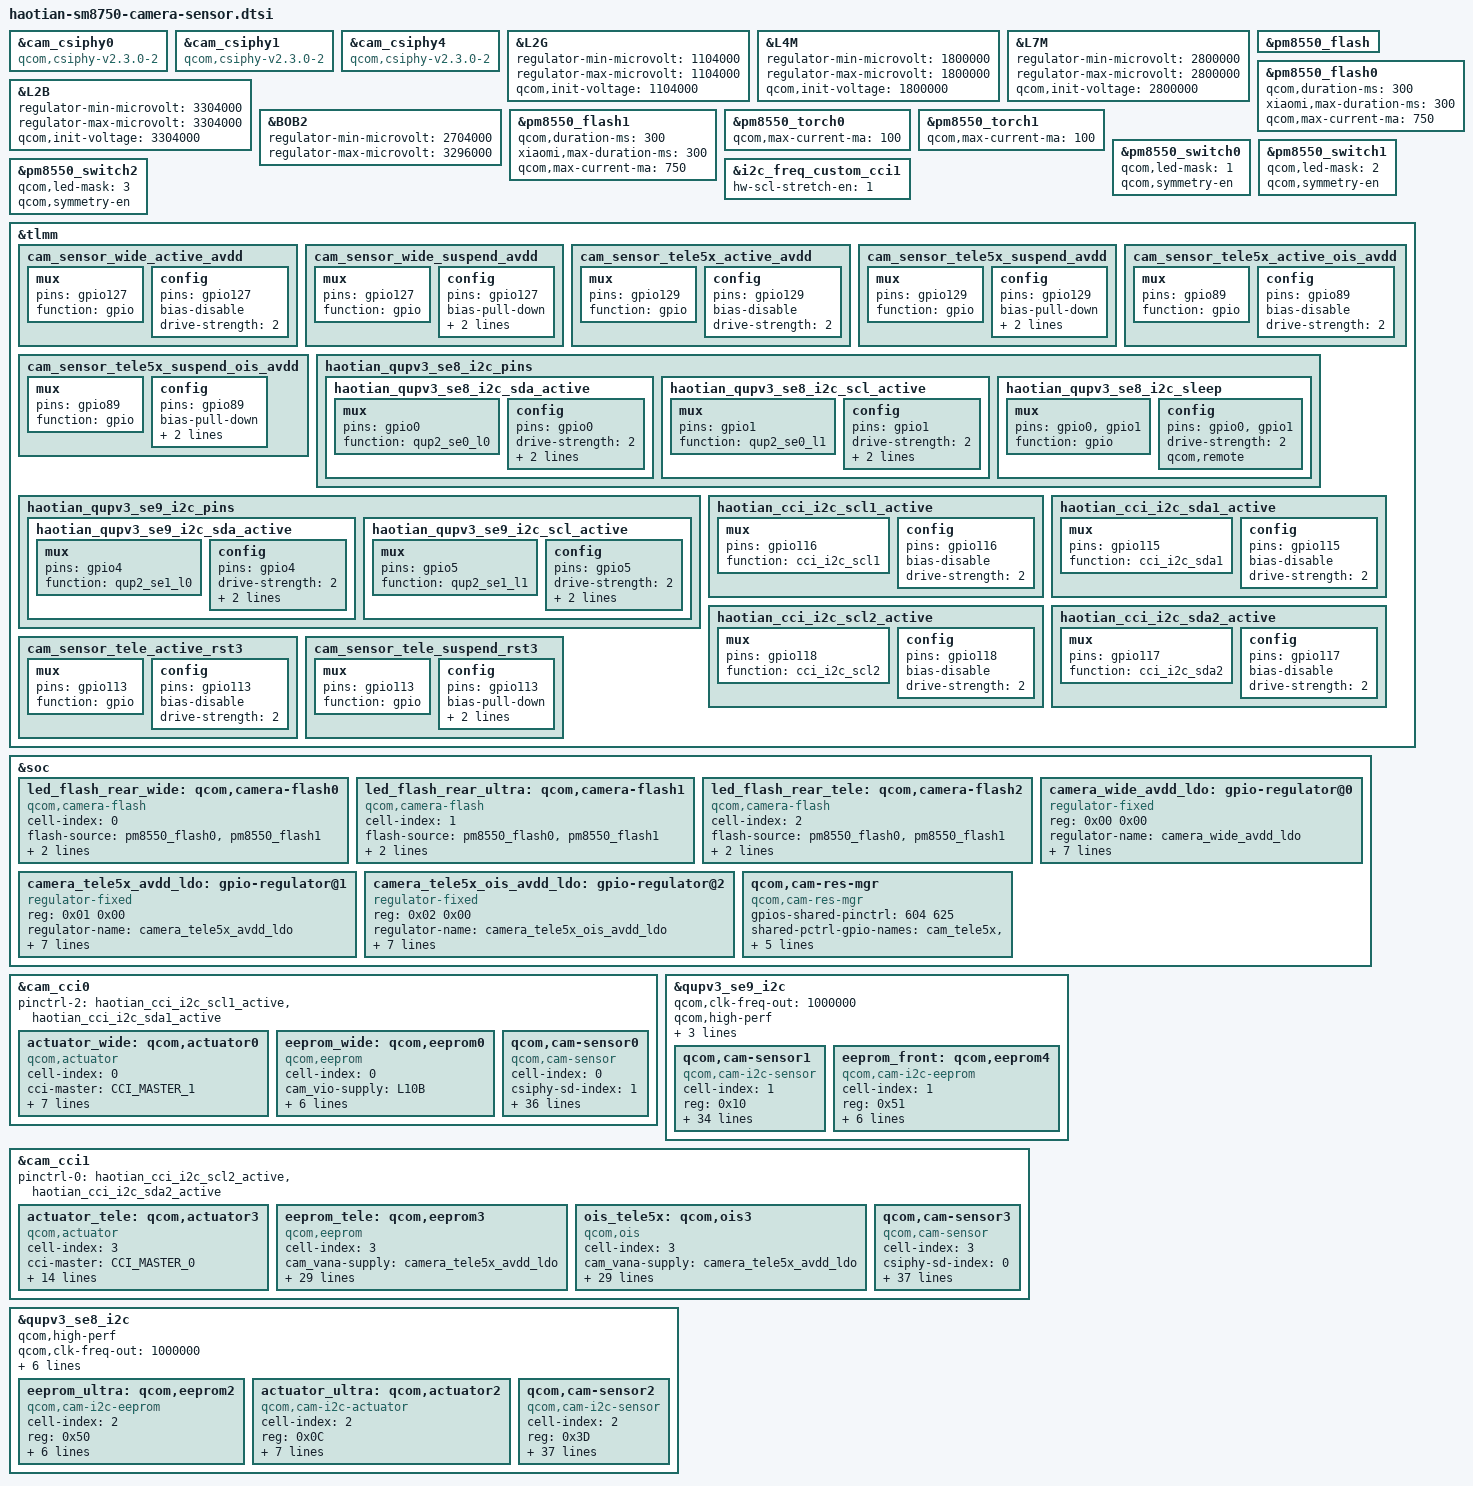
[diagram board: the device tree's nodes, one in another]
#include <dt-bindings/msm-camera.h>

// tele5x
&cam_csiphy0 {
	compatible = "qcom,csiphy-v2.3.0-2", "qcom,csiphy";
};

// Wide
&cam_csiphy1 {
	compatible = "qcom,csiphy-v2.3.0-2", "qcom,csiphy";
};

// Front
&cam_csiphy4 {
	compatible = "qcom,csiphy-v2.3.0-2", "qcom,csiphy";
};

&L2G {
	regulator-min-microvolt = <1104000>;
	regulator-max-microvolt = <1104000>;
	qcom,init-voltage = <1104000>;
};

&L4M {
	regulator-min-microvolt = <1800000>;
	regulator-max-microvolt = <1800000>;
	qcom,init-voltage = <1800000>;
};

&L7M {
	regulator-min-microvolt = <2800000>;
	regulator-max-microvolt = <2800000>;
	qcom,init-voltage = <2800000>;
};

&L2B {
	regulator-min-microvolt = <3304000>;
	regulator-max-microvolt = <3304000>;
	qcom,init-voltage = <3304000>;
};

&BOB2 {
	regulator-min-microvolt = <2704000>;
	regulator-max-microvolt = <3296000>;
};

&pm8550_flash {
	status = "ok";
};

&pm8550_flash0 {
	qcom,duration-ms = <300>;
	xiaomi,max-duration-ms = <300>;
	qcom,max-current-ma = <750>;
};

&pm8550_flash1 {
	qcom,duration-ms = <300>;
	xiaomi,max-duration-ms = <300>;
	qcom,max-current-ma = <750>;
};

&pm8550_torch0{
	qcom,max-current-ma = <100>;
};

&pm8550_torch1{
	qcom,max-current-ma = <100>;
};

&pm8550_switch0 {
	qcom,led-mask = <1>;
	qcom,symmetry-en;
};

&pm8550_switch1 {
	qcom,led-mask = <2>;
	qcom,symmetry-en;
};

&pm8550_switch2 {
	qcom,led-mask = <3>;
	qcom,symmetry-en;
};

&i2c_freq_custom_cci1{
	hw-scl-stretch-en = <1>;
};

&tlmm {
	cam_sensor_wide_active_avdd: cam_sensor_wide_active_avdd {
		mux {
			pins = "gpio127";
			function = "gpio";
		};

		config {
			pins = "gpio127";
			bias-disable; /* No PULL */
			drive-strength = <2>; /* 2 MA */
		};
	};

	cam_sensor_wide_suspend_avdd: cam_sensor_wide_suspend_avdd {
		mux {
			pins = "gpio127";
			function = "gpio";
		};

		config {
			pins = "gpio127";
			bias-pull-down; /* PULL DOWN */
			drive-strength = <2>; /* 2 MA */
			output-low;
		};
	};

	cam_sensor_tele5x_active_avdd: cam_sensor_tele5x_active_avdd {
		mux {
			pins = "gpio129";
			function = "gpio";
		};

		config {
			pins = "gpio129";
			bias-disable; /* No PULL */
			drive-strength = <2>; /* 2 MA */
		};
	};

	cam_sensor_tele5x_suspend_avdd: cam_sensor_tele5x_suspend_avdd {
		mux {
			pins = "gpio129";
			function = "gpio";
		};

		config {
			pins = "gpio129";
			bias-pull-down; /* PULL DOWN */
			drive-strength = <2>; /* 2 MA */
			output-low;
		};
	};

	cam_sensor_tele5x_active_ois_avdd: cam_sensor_tele5x_active_ois_avdd {
		mux {
			pins = "gpio89";
			function = "gpio";
		};

		config {
			pins = "gpio89";
			bias-disable; /* No PULL */
			drive-strength = <2>; /* 2 MA */
		};
	};

	cam_sensor_tele5x_suspend_ois_avdd: cam_sensor_tele5x_suspend_ois_avdd {
		mux {
			pins = "gpio89";
			function = "gpio";
		};

		config {
			pins = "gpio89";
			bias-pull-down; /* PULL DOWN */
			drive-strength = <2>; /* 2 MA */
			output-low;
		};
	};

	haotian_qupv3_se8_i2c_pins: haotian_qupv3_se8_i2c_pins {
		haotian_qupv3_se8_i2c_sda_active: haotian_qupv3_se8_i2c_sda_active {
			mux {
				pins = "gpio0";
				function = "qup2_se0_l0";
			};

			config {
				pins = "gpio0";
				drive-strength = <2>;
				bias-disable;
				qcom,apps;
			};
		};

		haotian_qupv3_se8_i2c_scl_active: haotian_qupv3_se8_i2c_scl_active {
			mux {
				pins = "gpio1";
				function = "qup2_se0_l1";
			};

			config {
				pins = "gpio1";
				drive-strength = <2>;
				bias-disable;
				qcom,apps;
			};
		};

		haotian_qupv3_se8_i2c_sleep: haotian_qupv3_se8_i2c_sleep {
			mux {
				pins = "gpio0", "gpio1";
				function = "gpio";
			};

			config {
				pins = "gpio0", "gpio1";
				drive-strength = <2>;
				qcom,remote;
			};
		};
	};


	haotian_qupv3_se9_i2c_pins: haotian_qupv3_se9_i2c_pins {
		haotian_qupv3_se9_i2c_sda_active: haotian_qupv3_se9_i2c_sda_active {
			mux {
				pins = "gpio4";
				function = "qup2_se1_l0";
			};

			config {
				pins = "gpio4";
				drive-strength = <2>;
				bias-disable;
				qcom,apps;
			};
		};

		haotian_qupv3_se9_i2c_scl_active: haotian_qupv3_se9_i2c_scl_active {
			mux {
				pins = "gpio5";
				function = "qup2_se1_l1";
			};

			config {
				pins = "gpio5";
				drive-strength = <2>;
				bias-disable;
				qcom,apps;
			};
		};
	};

	haotian_cci_i2c_scl1_active: haotian_cci_i2c_scl1_active {
		mux {
			/* CLK, DATA */
			pins = "gpio116";
			function = "cci_i2c_scl1";
		};

		config {
			pins = "gpio116";
			bias-disable; /* NO PULL */
			drive-strength = <2>; /* 2 MA */
		};
	};

	haotian_cci_i2c_sda1_active: haotian_cci_i2c_sda1_active {
		mux {
			/* CLK, DATA */
			pins = "gpio115";
			function = "cci_i2c_sda1";
		};

		config {
			pins = "gpio115";
			bias-disable; /* NO PULL */
			drive-strength = <2>; /* 2 MA */
		};
	};

	haotian_cci_i2c_scl2_active: haotian_cci_i2c_scl2_active {
		mux {
			/* CLK, DATA */
			pins = "gpio118";
			function = "cci_i2c_scl2";
		};

		config {
			pins = "gpio118";
			bias-disable; /* NO PULL */
			drive-strength = <2>; /* 2 MA */
		};
	};

	haotian_cci_i2c_sda2_active: haotian_cci_i2c_sda2_active {
		mux {
			/* CLK, DATA */
			pins = "gpio117";
			function = "cci_i2c_sda2";
		};

		config {
			pins = "gpio117";
			bias-disable; /* NO PULL */
			drive-strength = <2>; /* 2 MA */
		};
	};

	cam_sensor_tele_active_rst3: cam_sensor_tele_active_rst3 {
		mux {
			pins = "gpio113";
			function = "gpio";
		};

		config {
			pins = "gpio113";
			bias-disable; /* No PULL */
			drive-strength = <2>; /* 2 MA */
		};
	};

	cam_sensor_tele_suspend_rst3: cam_sensor_tele_suspend_rst3 {
		mux {
			pins = "gpio113";
			function = "gpio";
		};

		config {
			pins = "gpio113";
			bias-pull-down; /* PULL DOWN */
			drive-strength = <2>; /* 2 MA */
			output-low;
		};
	};
};

&soc {
	led_flash_rear_wide: qcom,camera-flash0 {
		cell-index = <0>;
		compatible = "qcom,camera-flash";
		flash-source = <&pm8550_flash0 &pm8550_flash1>;
		torch-source = <&pm8550_torch0 &pm8550_torch1>;
		switch-source = <&pm8550_switch2>;
		status = "ok";
	};

	led_flash_rear_ultra: qcom,camera-flash1 {
		cell-index = <1>;
		compatible = "qcom,camera-flash";
		flash-source = <&pm8550_flash0 &pm8550_flash1>;
		torch-source = <&pm8550_torch0 &pm8550_torch1>;
		switch-source = <&pm8550_switch2>;
		status = "ok";
	};

	led_flash_rear_tele: qcom,camera-flash2 {
		cell-index = <2>;
		compatible = "qcom,camera-flash";
		flash-source = <&pm8550_flash0 &pm8550_flash1>;
		torch-source = <&pm8550_torch0 &pm8550_torch1>;
		switch-source = <&pm8550_switch2>;
		status = "ok";
	};

	camera_wide_avdd_ldo: gpio-regulator@0 {
		compatible = "regulator-fixed";
		reg = <0x00 0x00>;
		regulator-name = "camera_wide_avdd_ldo";
		regulator-min-microvolt = <2800000>;
		regulator-max-microvolt = <2800000>;
		regulator-enable-ramp-delay = <100>;
		enable-active-high;
		gpio = <&tlmm 127 0>;
		pinctrl-names = "wide_avdd_active", "wide_avdd_suspend";
		pinctrl-0 = <&cam_sensor_wide_active_avdd
					 &cam_sensor_wide_suspend_avdd>;
	};

	camera_tele5x_avdd_ldo: gpio-regulator@1 {
		compatible = "regulator-fixed";
		reg = <0x01 0x00>;
		regulator-name = "camera_tele5x_avdd_ldo";
		regulator-min-microvolt = <2800000>;
		regulator-max-microvolt = <2800000>;
		regulator-enable-ramp-delay = <100>;
		enable-active-high;
		gpio = <&tlmm 129 0>;
		pinctrl-names = "tele5x_avdd_active", "tele5x_avdd_suspend";
		pinctrl-0 = <&cam_sensor_tele5x_active_avdd
					 &cam_sensor_tele5x_suspend_avdd>;
	};

	camera_tele5x_ois_avdd_ldo: gpio-regulator@2 {
		compatible = "regulator-fixed";
		reg = <0x02 0x00>;
		regulator-name = "camera_tele5x_ois_avdd_ldo";
		regulator-min-microvolt = <2800000>;
		regulator-max-microvolt = <2800000>;
		regulator-enable-ramp-delay = <100>;
		enable-active-high;
		gpio = <&tlmm 89 0>;
		pinctrl-names = "tele5x_ois_avdd_active", "tele5x_ois_avdd_suspend";
		pinctrl-0 = <&cam_sensor_tele5x_active_ois_avdd
					 &cam_sensor_tele5x_suspend_ois_avdd>;
	};

	qcom,cam-res-mgr {
		compatible = "qcom,cam-res-mgr";
		gpios-shared-pinctrl = <604 625>;
		shared-pctrl-gpio-names = "cam_tele5x", "cam_tele5x";
		pinctrl-names = "cam_tele5x_active", "cam_tele5x_suspend";
		pinctrl-0 = <&cam_sensor_mclk3_active
					&cam_sensor_tele_active_rst3>;
		pinctrl-1 = <&cam_sensor_mclk3_suspend
					&cam_sensor_tele_suspend_rst3>;
		status = "ok";
	};
};

&cam_cci0 {
	pinctrl-2 = <&haotian_cci_i2c_scl1_active &haotian_cci_i2c_sda1_active>;

	// wide actuator
	actuator_wide: qcom,actuator0 {
		cell-index = <0>;
		compatible = "qcom,actuator";
		cci-master = <CCI_MASTER_1>;
		cam_vaf-supply = <&L2B>;
		cam_vio-supply = <&L10B>;
		regulator-names = "cam_vaf", "cam_vio";
		rgltr-cntrl-support;
		rgltr-min-voltage = <3304000 1800000>;
		rgltr-max-voltage = <3304000 1800000>;
		rgltr-load-current = <150000 150000>;
	};

	eeprom_wide: qcom,eeprom0 {
		cell-index = <0>;
		compatible = "qcom,eeprom";
		cam_vio-supply = <&L10B>;
		regulator-names = "cam_vio";
		rgltr-cntrl-support;
		rgltr-min-voltage = <1800000>;
		rgltr-max-voltage = <1800000>;
		rgltr-load-current = <50000>;
		cci-master = <CCI_MASTER_1>;
		status = "ok";
	};

	// wide sensor
	qcom,cam-sensor0 {
		cell-index = <0>;
		compatible = "qcom,cam-sensor";
		csiphy-sd-index = <1>;
		eeprom-src = <&eeprom_wide>;
		actuator-src = <&actuator_wide>;
		led-flash-src = <&led_flash_rear_wide>;
		sensor-position-roll = <90>;
		sensor-position-pitch = <0>;
		sensor-position-yaw = <180>;
		cam_vana-supply = <&camera_wide_avdd_ldo>;
		cam_vio-supply = <&L10B>;
		cam_vdig-supply = <&L1I>;
		cam_clk-supply = <&cam_cc_titan_top_gdsc>;
		cam_vaf-supply = <&L2B>;
		cam_bob2-supply = <&BOB2>;
		regulator-names = "cam_vana", "cam_vio", "cam_vdig",
			"cam_clk","cam_vaf", "cam_bob2";
		rgltr-cntrl-support;
		rgltr-min-voltage = <2800000 1800000 1200000 0 3304000 2704000>;
		rgltr-max-voltage = <2800000 1800000 1200000 0 3304000 3296000>;
		rgltr-load-current = <150000 150000 150000 0 150000 2000000>;
		gpio-no-mux = <0>;
		pinctrl-names = "cam_default", "cam_suspend";
		pinctrl-0 = <&cam_sensor_mclk1_active &cam_sensor_i3cSelect_active>;
		pinctrl-1 = <&cam_sensor_mclk1_suspend &cam_sensor_i3cSelect_suspend>;
		gpios = <&tlmm 90 0>, <&tlmm 6 0>;
		gpio-reset = <1>;
		gpio-req-tbl-num = <0 1>;
		gpio-req-tbl-flags = <1 0>;
		gpio-req-tbl-label = "CAMIF_MCLK1", "CAM_I3CSELECT";
		cci-master = <CCI_MASTER_1>;
		clocks = <&cambistmclkcc CAM_BIST_MCLK_CC_MCLK1_CLK>;
		clock-names = "cam_clk";
		clock-cntl-level = "nominal";
		clock-rates = <19200000>;
		status = "ok";
	};
};

&qupv3_se9_i2c {
	status = "ok";
	qcom,clk-freq-out = <1000000>;
	qcom,high-perf;
	qcom,pm-ctrl-client;
	pinctrl-0 = <&haotian_qupv3_se9_i2c_scl_active>, <&haotian_qupv3_se9_i2c_sda_active>;

	// Front Sensor
	qcom,cam-sensor1 {
		cell-index = <1>;
		reg = <0x10>;
		compatible = "qcom,cam-i2c-sensor";
		csiphy-sd-index = <4>;
		eeprom-src = <&eeprom_front>;
		sensor-position-roll = <270>;
		sensor-position-pitch = <0>;
		sensor-position-yaw = <0>;
		cam_vana-supply = <&L3M>;
		cam_vio-supply = <&L5M>;
		cam_vdig-supply = <&L1M>;
		cam_clk-supply = <&cam_cc_titan_top_gdsc>;
		cam_bob2-supply = <&BOB2>;
		regulator-names = "cam_vana", "cam_vio",
			"cam_vdig", "cam_clk", "cam_bob2";
		rgltr-cntrl-support;
		aon-camera-id = <AON_CAM1>;
		rgltr-min-voltage = <2800000 1800000 1104000 0 2704000>;
		rgltr-max-voltage = <2800000 1800000 1104000 0 3296000>;
		rgltr-load-current = <150000 150000 150000 0 2000000>;
		gpio-no-mux = <0>;
		pinctrl-names = "cam_default", "cam_suspend";
		pinctrl-0 = <&cam_sensor_mclk4_active
			&cam_sensor_active_rst4>;
		pinctrl-1 = <&cam_sensor_mclk4_suspend
			&cam_sensor_suspend_rst4>;
		gpios = <&tlmm 93 0>, <&tlmm 7 0>;
		gpio-reset = <1>;
		gpio-req-tbl-num = <0 1>;
		gpio-req-tbl-flags = <1 0>;
		gpio-req-tbl-label = "CAMIF_MCLK4", "CAM_RESET4";
		clocks = <&cambistmclkcc CAM_BIST_MCLK_CC_MCLK4_CLK>;
		clock-names = "cam_clk";
		clock-cntl-level = "nominal";
		clock-rates = <19200000>;
		status = "ok";
	};

	//front
	eeprom_front: qcom,eeprom4 {
		cell-index = <1>;
		reg = <0x51>;
		compatible = "qcom,cam-i2c-eeprom";
		cam_vio-supply = <&L5M>;
		regulator-names = "cam_vio";
		rgltr-cntrl-support;
		rgltr-min-voltage = <1800000>;
		rgltr-max-voltage = <1800000>;
		rgltr-load-current = <150000>;
		status = "ok";
	};

};

&cam_cci1 {
	pinctrl-0 = <&haotian_cci_i2c_scl2_active &haotian_cci_i2c_sda2_active>;

	actuator_tele: qcom,actuator3 {
		cell-index = <3>;
		compatible = "qcom,actuator";
		cci-master = <CCI_MASTER_0>;
		cam_vaf-supply = <&L16B>;
		cam_vio-supply = <&L10B>;
		cam_v_custom1-supply = <&camera_tele5x_ois_avdd_ldo>;/*OIS AVDD*/
		cam_bob2-supply = <&BOB2>;
		regulator-names = "cam_vaf", "cam_vio", "cam_v_custom1", "cam_bob2";
		rgltr-cntrl-support;
		rgltr-min-voltage = <2800000 1800000 2800000 2704000>;
		rgltr-max-voltage = <2800000 1800000 2800000 3296000>;
		rgltr-load-current = <150000 20000 150000 2000000>;
		status = "ok";
	};

	eeprom_tele: qcom,eeprom3 {
		cell-index = <3>;
		compatible = "qcom,eeprom";
		cam_vana-supply = <&camera_tele5x_avdd_ldo>;
		cam_vio-supply = <&L10B>;
		cam_vdig-supply = <&L2G>;
		cam_vaf-supply = <&L16B>;
		cam_v_custom1-supply = <&camera_tele5x_ois_avdd_ldo>;/*OIS AVDD*/
		cam_bob2-supply = <&BOB2>;
		cam_clk-supply = <&cam_cc_titan_top_gdsc>;
		regulator-names = "cam_vana", "cam_vio", "cam_vdig",
			"cam_vaf", "cam_v_custom1", "cam_clk", "cam_bob2";
		rgltr-cntrl-support;
		rgltr-min-voltage = <2800000 1800000 1104000 2800000 2800000 0 2704000>;
		rgltr-max-voltage = <2800000 1800000 1104000 2800000 2800000 0 3296000>;
		rgltr-load-current = <150000 150000 150000 150000 150000 0 2000000>;
		gpio-no-mux = <0>;
		use-shared-clk;
		gpios = <&tlmm 92 0>, <&tlmm 113 0>;
		gpio-reset = <1>;
		gpio-req-tbl-num = <0 1>;
		gpio-req-tbl-flags = <1 0>;
		gpio-req-tbl-label = "CAMIF_MCLK3", "CAM_RESET_TELE5X";
		cci-master = <CCI_MASTER_0>;
		clocks = <&cambistmclkcc CAM_BIST_MCLK_CC_MCLK3_CLK>;
		clock-names = "cam_clk";
		clock-cntl-level = "nominal";
		clock-rates = <19200000>;
		status = "ok";
	};

	ois_tele5x: qcom,ois3 {
		cell-index = <3>;
		compatible = "qcom,ois";
		cam_vana-supply = <&camera_tele5x_avdd_ldo>;
		cam_vio-supply = <&L10B>;
		cam_vdig-supply = <&L2G>;
		cam_vaf-supply = <&L16B>;
		cam_v_custom1-supply = <&camera_tele5x_ois_avdd_ldo>;/*OIS AVDD*/
		cam_bob2-supply = <&BOB2>;
		cam_clk-supply = <&cam_cc_titan_top_gdsc>;
		regulator-names = "cam_vana", "cam_vio", "cam_vdig",
			"cam_vaf", "cam_v_custom1", "cam_clk", "cam_bob2";
		rgltr-cntrl-support;
		rgltr-min-voltage = <2800000 1800000 1104000 2800000 2800000 0 2704000>;
		rgltr-max-voltage = <2800000 1800000 1104000 2800000 2800000 0 3296000>;
		rgltr-load-current = <150000 150000 150000 150000 150000 0 2000000>;
		gpio-no-mux = <0>;
		use-shared-clk;
		gpios = <&tlmm 92 0>, <&tlmm 113 0>;
		gpio-reset = <1>;
		gpio-req-tbl-num = <0 1>;
		gpio-req-tbl-flags = <1 0>;
		gpio-req-tbl-label = "CAMIF_MCLK3", "CAM_RESET_TELE5X";
		cci-master = <CCI_MASTER_0>;
		clocks = <&cambistmclkcc CAM_BIST_MCLK_CC_MCLK3_CLK>;
		clock-names = "cam_clk";
		clock-cntl-level = "nominal";
		clock-rates = <19200000>;
		status = "ok";
	};

	// Tele5x sensor
	qcom,cam-sensor3 {
		cell-index = <3>;
		compatible = "qcom,cam-sensor";
		csiphy-sd-index = <0>;
		eeprom-src = <&eeprom_tele>;
		actuator-src = <&actuator_tele>;
		ois-src = <&ois_tele5x>;
		led-flash-src = <&led_flash_rear_tele>;
		sensor-position-roll = <90>;
		sensor-position-pitch = <0>;
		sensor-position-yaw = <180>;
		cam_vana-supply = <&camera_tele5x_avdd_ldo>;
		cam_vio-supply = <&L10B>;
		cam_vdig-supply = <&L2G>;
		cam_vaf-supply = <&L16B>;
		cam_v_custom1-supply = <&camera_tele5x_ois_avdd_ldo>;/*OIS AVDD*/
		cam_bob2-supply = <&BOB2>;
		cam_clk-supply = <&cam_cc_titan_top_gdsc>;
		regulator-names = "cam_vana", "cam_vio", "cam_vdig",
			"cam_vaf", "cam_v_custom1", "cam_clk", "cam_bob2";
		rgltr-cntrl-support;
		rgltr-min-voltage = <2800000 1800000 1104000 2800000 2800000 0 2704000>;
		rgltr-max-voltage = <2800000 1800000 1104000 2800000 2800000 0 3296000>;
		rgltr-load-current = <150000 150000 150000 150000 150000 0 2000000>;
		gpio-no-mux = <0>;
		use-shared-clk;
		gpios = <&tlmm 92 0>, <&tlmm 113 0>;
		gpio-reset = <1>;
		gpio-req-tbl-num = <0 1>;
		gpio-req-tbl-flags = <1 0>;
		gpio-req-tbl-label = "CAMIF_MCLK3", "CAM_RESET_TELE5X";
		cci-master = <CCI_MASTER_0>;
		clocks = <&cambistmclkcc CAM_BIST_MCLK_CC_MCLK3_CLK>;
		clock-names = "cam_clk";
		clock-cntl-level = "nominal";
		clock-rates = <19200000>;
		status = "ok";
	};
};

&qupv3_se8_i2c {
	status = "ok";
	qcom,high-perf;
	qcom,clk-freq-out = <1000000>;
	qcom,pm-ctrl-client;
	pinctrl-0 = <&haotian_qupv3_se8_i2c_sda_active>, <&haotian_qupv3_se8_i2c_scl_active>;
	pinctrl-1 = <&haotian_qupv3_se8_i2c_sleep>;
	dmas = <&gpi_dma2 0 0 3 1024 0>,
		<&gpi_dma2 1 0 3 1024 0>;

	//ultra
	eeprom_ultra: qcom,eeprom2 {
		cell-index = <2>;
		reg = <0x50>;
		compatible = "qcom,cam-i2c-eeprom";
		cam_vio-supply = <&L4M>;
		regulator-names = "cam_vio";
		rgltr-cntrl-support;
		rgltr-min-voltage = <1800000>;
		rgltr-max-voltage = <1800000>;
		rgltr-load-current = <150000>;
		status = "ok";
	};

	actuator_ultra: qcom,actuator2 {
		cell-index = <2>;
		reg = <0x0C>;
		compatible = "qcom,cam-i2c-actuator";
		cam_vaf-supply = <&L7M>;
		cam_vio-supply = <&L4M>;
		regulator-names = "cam_vaf", "cam_vio";
		rgltr-cntrl-support;
		rgltr-min-voltage = <2800000 1800000>;
		rgltr-max-voltage = <2800000 1800000>;
		rgltr-load-current = <103000 150000>;
		status = "ok";
	};

	qcom,cam-sensor2 {
		cell-index = <2>;
		reg = <0x3D>;
		compatible = "qcom,cam-i2c-sensor";
		csiphy-sd-index = <2>;
		led-flash-src = <&led_flash_rear_ultra>;
		sensor-position-roll = <90>;
		sensor-position-pitch = <0>;
		sensor-position-yaw = <180>;
		actuator-src = <&actuator_ultra>;
		eeprom-src = <&eeprom_ultra>;
		cam_vio-supply = <&L4M>;
		cam_vdig-supply = <&L2M>;
		cam_clk-supply = <&cam_cc_titan_top_gdsc>;
		cam_vana-supply = <&L6M>;
		cam_vaf-supply = <&L7M>;
		cam_bob2-supply = <&BOB2>;
		regulator-names = "cam_vio", "cam_vdig", "cam_clk",
			"cam_vana", "cam_vaf", "cam_bob2";
		rgltr-cntrl-support;
		aon-camera-id = <AON_CAM2>;
		rgltr-min-voltage = <1800000 1056000 0 2800000 2800000 2704000>;
		rgltr-max-voltage = <1800000 1056000 0 2800000 2800000 3296000>;
		rgltr-load-current = <150000 150000 0 150000 103000 2000000>;
		gpio-no-mux = <0>;
		pinctrl-names = "cam_default", "cam_suspend";
		pinctrl-0 = <&cam_sensor_mclk2_active
					&cam_sensor_active_rst2>;
		pinctrl-1 = <&cam_sensor_mclk2_suspend
					&cam_sensor_suspend_rst2>;
		gpios = <&tlmm 91 0>, <&tlmm 3 0>;
		gpio-reset = <1>;
		gpio-req-tbl-num = <0 1>;
		gpio-req-tbl-flags = <1 0>;
		gpio-req-tbl-label = "CAMUW_MCLK2", "CAMUW_RESET2";
		clocks = <&cambistmclkcc CAM_BIST_MCLK_CC_MCLK2_CLK>;
		clock-names = "cam_clk";
		clock-cntl-level = "nominal";
		clock-rates = <19200000>;
		status = "ok";
	};
};
